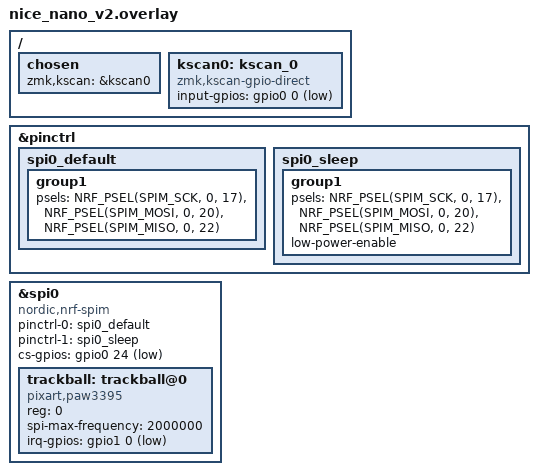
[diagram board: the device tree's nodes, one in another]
#include <dt-bindings/zmk/matrix_transform.h>
#include <dt-bindings/gpio/nordic-nrf-gpio.h>

/ {
    /* Фиктивный kscan, чтобы прошивка не выдавала ошибку "нет клавиатуры" */
    chosen {
        zmk,kscan = &kscan0;
    };

    kscan0: kscan_0 {
        compatible = "zmk,kscan-gpio-direct";
        input-gpios = <&gpio0 0 (GPIO_ACTIVE_LOW | GPIO_PULL_UP)>;
    };
};

&pinctrl {
    spi0_default: spi0_default {
        group1 {
            psels = <NRF_PSEL(SPIM_SCK, 0, 17)>,  /* P0.17 */
                    <NRF_PSEL(SPIM_MOSI, 0, 20)>, /* P0.20 */
                    <NRF_PSEL(SPIM_MISO, 0, 22)>; /* P0.22 */
        };
    };
    spi0_sleep: spi0_sleep {
        group1 {
            psels = <NRF_PSEL(SPIM_SCK, 0, 17)>,
                    <NRF_PSEL(SPIM_MOSI, 0, 20)>,
                    <NRF_PSEL(SPIM_MISO, 0, 22)>;
            low-power-enable;
        };
    };
};

&spi0 {
    status = "okay";
    compatible = "nordic,nrf-spim";
    pinctrl-0 = <&spi0_default>;
    pinctrl-1 = <&spi0_sleep>;
    pinctrl-names = "default", "sleep";
    
    /* CS пин (P0.24) */
    cs-gpios = <&gpio0 24 GPIO_ACTIVE_LOW>; 

    trackball: trackball@0 {
        status = "okay";
        compatible = "pixart,paw3395";
        reg = <0>;
        spi-max-frequency = <2000000>;
        
        /* INT (IRQ) пин (P1.00) */
        irq-gpios = <&gpio1 0 (GPIO_ACTIVE_LOW | GPIO_PULL_UP)>; 
    };
};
